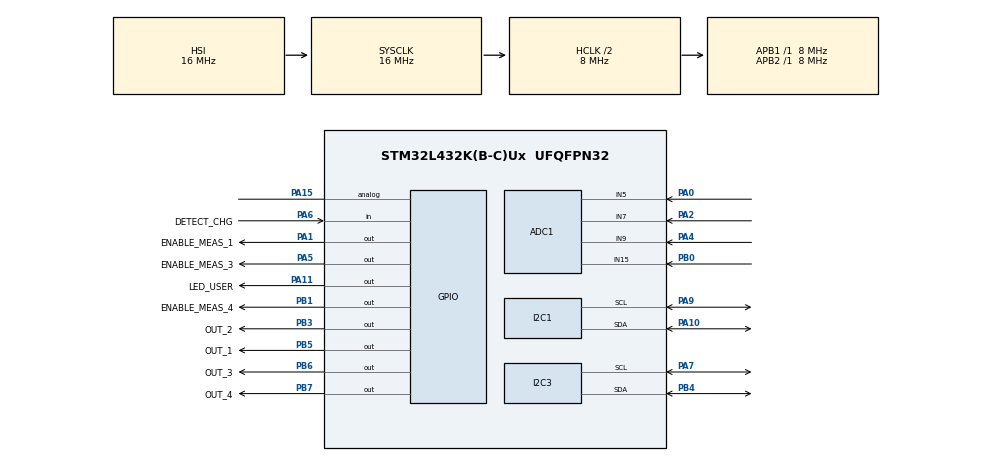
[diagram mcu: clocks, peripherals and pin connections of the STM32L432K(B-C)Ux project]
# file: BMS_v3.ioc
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ADC1.Channel-0\#ChannelRegularConversion=ADC_CHANNEL_5
ADC1.NbrOfConversion=1
ADC1.NbrOfConversionFlag=1
ADC1.master=1
I2C1.OwnAddress=4
I2C1.Timing=0x2000090E
I2C3.Timing=0x2000090E
Mcu.Family=STM32L4
Mcu.Name=STM32L432K(B-C)Ux
Mcu.Package=UFQFPN32
NVIC.I2C1_ER_IRQn=true\:0\:0\:false\:false\:true\:true\:true\:true
NVIC.I2C1_EV_IRQn=true\:0\:0\:false\:false\:true\:true\:true\:true
NVIC.PriorityGroup=NVIC_PRIORITYGROUP_4
PA0.Signal=ADCx_IN5
PA1.GPIO_Label=ENABLE_MEAS_1
PA1.Signal=GPIO_Output
PA10.Mode=I2C
PA10.Signal=I2C1_SDA
PA11.GPIO_Label=LED_USER
PA11.Signal=GPIO_Output
PA13\ (JTMS-SWDIO).Mode=Serial_Wire
PA13\ (JTMS-SWDIO).Signal=SYS_JTMS-SWDIO
PA14\ (JTCK-SWCLK).Mode=Serial_Wire
PA14\ (JTCK-SWCLK).Signal=SYS_JTCK-SWCLK
PA15\ (JTDI).Signal=GPIO_Analog
PA2.Signal=ADCx_IN7
PA4.Signal=ADCx_IN9
PA5.GPIO_Label=ENABLE_MEAS_3
PA5.Signal=GPIO_Output
PA6.GPIO_Label=DETECT_CHG
PA6.GPIO_PuPd=GPIO_PULLUP
PA6.Signal=GPIO_Input
PA7.Mode=I2C
PA7.Signal=I2C3_SCL
PA9.Mode=I2C
PA9.Signal=I2C1_SCL
PB0.Signal=ADCx_IN15
PB1.GPIO_Label=ENABLE_MEAS_4
PB1.Signal=GPIO_Output
PB3\ (JTDO-TRACESWO).GPIO_Label=OUT_2
PB3\ (JTDO-TRACESWO).Signal=GPIO_Output
PB4\ (NJTRST).Mode=I2C
PB4\ (NJTRST).Signal=I2C3_SDA
PB5.GPIO_Label=OUT_1
PB5.Signal=GPIO_Output
PB6.GPIO_Label=OUT_3
PB6.Signal=GPIO_Output
PB7.GPIO_Label=OUT_4
PB7.Signal=GPIO_Output
ProjectManager.HeapSize=0x200
ProjectManager.StackSize=0x400
ProjectManager.TargetToolchain=STM32CubeIDE
RCC.ADCFreq_Value=32000000
RCC.AHBCLKDivider=RCC_SYSCLK_DIV2
RCC.AHBFreq_Value=8000000
RCC.APB1Freq_Value=8000000
RCC.APB1TimFreq_Value=8000000
RCC.APB2Freq_Value=8000000
RCC.APB2TimFreq_Value=8000000
RCC.CortexFreq_Value=8000000
RCC.HCLKFreq_Value=8000000
RCC.HSE_VALUE=8000000
RCC.HSI48_VALUE=48000000
RCC.HSI_VALUE=16000000
RCC.LSE_VALUE=32768
RCC.MSI_VALUE=4000000
RCC.PLLSAI1N=16
RCC.SYSCLKFreq_VALUE=16000000
RCC.SYSCLKSource=RCC_SYSCLKSOURCE_HSI
RCC.USBFreq_Value=32000000
RCC.VCOOutputFreq_Value=32000000
SH.ADCx_IN15.0=ADC1_IN15,IN15-Single-Ended
SH.ADCx_IN5.0=ADC1_IN5,IN5-Single-Ended
SH.ADCx_IN7.0=ADC1_IN7,IN7-Single-Ended
SH.ADCx_IN9.0=ADC1_IN9,IN9-Single-Ended
board=custom

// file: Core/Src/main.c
/* USER CODE BEGIN Header */
/**
  ******************************************************************************
  * @file           : main.c
  * @brief          : Main program body
  ******************************************************************************
  * @attention
  *
  * Copyright (c) 2022 STMicroelectronics.
  * All rights reserved.
  *
  * This software is licensed under terms that can be found in the LICENSE file
  * in the root directory of this software component.
  * If no LICENSE file comes with this software, it is provided AS-IS.
  *
  ******************************************************************************
  */
/* USER CODE END Header */
#include "main.h"

ADC_HandleTypeDef hadc1;

I2C_HandleTypeDef hi2c1;
I2C_HandleTypeDef hi2c3;

void SystemClock_Config(void);
static void MX_GPIO_Init(void);
static void MX_I2C1_Init(void);
static void MX_ADC1_Init(void);
static void MX_I2C3_Init(void);

int main(void)
{

  /* MCU Configuration--------------------------------------------------------*/

  /* Reset of all peripherals, Initializes the Flash interface and the Systick. */
  HAL_Init();

  /* Configure the system clock */
  SystemClock_Config();

  /* Initialize all configured peripherals */
  MX_GPIO_Init();
  MX_I2C1_Init();
  MX_ADC1_Init();
  MX_I2C3_Init();
  /* USER CODE BEGIN 2 */

  firmware();

  HAL_Delay(250);
  // Set all Outputs to ON

//  HAL_GPIO_TogglePin(LED_LOW_GPIO_Port, LED_LOW_Pin);
  /* USER CODE END 2 */

  /* Infinite loop */
  while (1)
  {

    /* USER CODE BEGIN 3 */
	  HAL_GPIO_WritePin(OUT_4_GPIO_Port, OUT_4_Pin, 1);

	  if (HAL_GPIO_ReadPin(DETECT_CHG_GPIO_Port, DETECT_CHG_Pin)) {
		  HAL_GPIO_WritePin(OUT_1_GPIO_Port, OUT_1_Pin, 1);
		  HAL_GPIO_WritePin(OUT_2_GPIO_Port, OUT_2_Pin, 1);
		  HAL_GPIO_WritePin(OUT_3_GPIO_Port, OUT_3_Pin, 1);
	  } else {
		  HAL_GPIO_WritePin(OUT_1_GPIO_Port, OUT_1_Pin, 0);
		  HAL_GPIO_WritePin(OUT_2_GPIO_Port, OUT_2_Pin, 0);
		  HAL_GPIO_WritePin(OUT_3_GPIO_Port, OUT_3_Pin, 0);
	  }

	  HAL_GPIO_TogglePin(LED_USER_GPIO_Port, LED_USER_Pin);
	  HAL_Delay(250);
  }
  /* USER CODE END 3 */
}

void SystemClock_Config(void)
{
  RCC_OscInitTypeDef RCC_OscInitStruct = {0};
  RCC_ClkInitTypeDef RCC_ClkInitStruct = {0};

  /** Configure the main internal regulator output voltage
  */
  if (HAL_PWREx_ControlVoltageScaling(PWR_REGULATOR_VOLTAGE_SCALE1) != HAL_OK)
  {
    Error_Handler();
  }

  /** Initializes the RCC Oscillators according to the specified parameters
  * in the RCC_OscInitTypeDef structure.
  */
  RCC_OscInitStruct.OscillatorType = RCC_OSCILLATORTYPE_HSI|RCC_OSCILLATORTYPE_MSI;
  RCC_OscInitStruct.HSIState = RCC_HSI_ON;
  RCC_OscInitStruct.HSICalibrationValue = RCC_HSICALIBRATION_DEFAULT;
  RCC_OscInitStruct.MSIState = RCC_MSI_ON;
  RCC_OscInitStruct.MSICalibrationValue = 0;
  RCC_OscInitStruct.MSIClockRange = RCC_MSIRANGE_6;
  RCC_OscInitStruct.PLL.PLLState = RCC_PLL_NONE;
  if (HAL_RCC_OscConfig(&RCC_OscInitStruct) != HAL_OK)
  {
    Error_Handler();
  }

  /** Initializes the CPU, AHB and APB buses clocks
  */
  RCC_ClkInitStruct.ClockType = RCC_CLOCKTYPE_HCLK|RCC_CLOCKTYPE_SYSCLK
                              |RCC_CLOCKTYPE_PCLK1|RCC_CLOCKTYPE_PCLK2;
  RCC_ClkInitStruct.SYSCLKSource = RCC_SYSCLKSOURCE_HSI;
  RCC_ClkInitStruct.AHBCLKDivider = RCC_SYSCLK_DIV2;
  RCC_ClkInitStruct.APB1CLKDivider = RCC_HCLK_DIV1;
  RCC_ClkInitStruct.APB2CLKDivider = RCC_HCLK_DIV1;

  if (HAL_RCC_ClockConfig(&RCC_ClkInitStruct, FLASH_LATENCY_0) != HAL_OK)
  {
    Error_Handler();
  }
}

static void MX_ADC1_Init(void)
{

  ADC_ChannelConfTypeDef sConfig = {0};

  /** Common config
  */
  hadc1.Instance = ADC1;
  hadc1.Init.ClockPrescaler = ADC_CLOCK_ASYNC_DIV1;
  hadc1.Init.Resolution = ADC_RESOLUTION_12B;
  hadc1.Init.DataAlign = ADC_DATAALIGN_RIGHT;
  hadc1.Init.ScanConvMode = ADC_SCAN_DISABLE;
  hadc1.Init.EOCSelection = ADC_EOC_SINGLE_CONV;
  hadc1.Init.LowPowerAutoWait = DISABLE;
  hadc1.Init.ContinuousConvMode = DISABLE;
  hadc1.Init.NbrOfConversion = 1;
  hadc1.Init.DiscontinuousConvMode = DISABLE;
  hadc1.Init.ExternalTrigConv = ADC_SOFTWARE_START;
  hadc1.Init.ExternalTrigConvEdge = ADC_EXTERNALTRIGCONVEDGE_NONE;
  hadc1.Init.DMAContinuousRequests = DISABLE;
  hadc1.Init.Overrun = ADC_OVR_DATA_PRESERVED;
  hadc1.Init.OversamplingMode = DISABLE;
  if (HAL_ADC_Init(&hadc1) != HAL_OK)
  {
    Error_Handler();
  }

  /** Configure Regular Channel
  */
  sConfig.Channel = ADC_CHANNEL_5;
  sConfig.Rank = ADC_REGULAR_RANK_1;
  sConfig.SamplingTime = ADC_SAMPLETIME_2CYCLES_5;
  sConfig.SingleDiff = ADC_SINGLE_ENDED;
  sConfig.OffsetNumber = ADC_OFFSET_NONE;
  sConfig.Offset = 0;
  if (HAL_ADC_ConfigChannel(&hadc1, &sConfig) != HAL_OK)
  {
    Error_Handler();
  }

}

static void MX_I2C1_Init(void)
{

  hi2c1.Instance = I2C1;
  hi2c1.Init.Timing = 0x2000090E;
  hi2c1.Init.OwnAddress1 = 8;
  hi2c1.Init.AddressingMode = I2C_ADDRESSINGMODE_7BIT;
  hi2c1.Init.DualAddressMode = I2C_DUALADDRESS_DISABLE;
  hi2c1.Init.OwnAddress2 = 0;
  hi2c1.Init.OwnAddress2Masks = I2C_OA2_NOMASK;
  hi2c1.Init.GeneralCallMode = I2C_GENERALCALL_DISABLE;
  hi2c1.Init.NoStretchMode = I2C_NOSTRETCH_DISABLE;
  if (HAL_I2C_Init(&hi2c1) != HAL_OK)
  {
    Error_Handler();
  }

  /** Configure Analogue filter
  */
  if (HAL_I2CEx_ConfigAnalogFilter(&hi2c1, I2C_ANALOGFILTER_ENABLE) != HAL_OK)
  {
    Error_Handler();
  }

  /** Configure Digital filter
  */
  if (HAL_I2CEx_ConfigDigitalFilter(&hi2c1, 0) != HAL_OK)
  {
    Error_Handler();
  }

}

static void MX_I2C3_Init(void)
{

  hi2c3.Instance = I2C3;
  hi2c3.Init.Timing = 0x2000090E;
  hi2c3.Init.OwnAddress1 = 0;
  hi2c3.Init.AddressingMode = I2C_ADDRESSINGMODE_7BIT;
  hi2c3.Init.DualAddressMode = I2C_DUALADDRESS_DISABLE;
  hi2c3.Init.OwnAddress2 = 0;
  hi2c3.Init.OwnAddress2Masks = I2C_OA2_NOMASK;
  hi2c3.Init.GeneralCallMode = I2C_GENERALCALL_DISABLE;
  hi2c3.Init.NoStretchMode = I2C_NOSTRETCH_DISABLE;
  if (HAL_I2C_Init(&hi2c3) != HAL_OK)
  {
    Error_Handler();
  }

  /** Configure Analogue filter
  */
  if (HAL_I2CEx_ConfigAnalogFilter(&hi2c3, I2C_ANALOGFILTER_ENABLE) != HAL_OK)
  {
    Error_Handler();
  }

  /** Configure Digital filter
  */
  if (HAL_I2CEx_ConfigDigitalFilter(&hi2c3, 0) != HAL_OK)
  {
    Error_Handler();
  }

}

static void MX_GPIO_Init(void)
{
  GPIO_InitTypeDef GPIO_InitStruct = {0};

  /* GPIO Ports Clock Enable */
  __HAL_RCC_GPIOA_CLK_ENABLE();
  __HAL_RCC_GPIOB_CLK_ENABLE();

  /*Configure GPIO pin Output Level */
  HAL_GPIO_WritePin(GPIOA, ENABLE_MEAS_1_Pin|ENABLE_MEAS_3_Pin|LED_USER_Pin, GPIO_PIN_RESET);

  /*Configure GPIO pin Output Level */
  HAL_GPIO_WritePin(GPIOB, ENABLE_MEAS_4_Pin|OUT_2_Pin|OUT_1_Pin|OUT_3_Pin
                          |OUT_4_Pin, GPIO_PIN_RESET);

  /*Configure GPIO pins : ENABLE_MEAS_1_Pin ENABLE_MEAS_3_Pin LED_USER_Pin */
  GPIO_InitStruct.Pin = ENABLE_MEAS_1_Pin|ENABLE_MEAS_3_Pin|LED_USER_Pin;
  GPIO_InitStruct.Mode = GPIO_MODE_OUTPUT_PP;
  GPIO_InitStruct.Pull = GPIO_NOPULL;
  GPIO_InitStruct.Speed = GPIO_SPEED_FREQ_LOW;
  HAL_GPIO_Init(GPIOA, &GPIO_InitStruct);

  /*Configure GPIO pin : DETECT_CHG_Pin */
  GPIO_InitStruct.Pin = DETECT_CHG_Pin;
  GPIO_InitStruct.Mode = GPIO_MODE_INPUT;
  GPIO_InitStruct.Pull = GPIO_PULLUP;
  HAL_GPIO_Init(DETECT_CHG_GPIO_Port, &GPIO_InitStruct);

  /*Configure GPIO pins : ENABLE_MEAS_4_Pin OUT_2_Pin OUT_1_Pin OUT_3_Pin
                           OUT_4_Pin */
  GPIO_InitStruct.Pin = ENABLE_MEAS_4_Pin|OUT_2_Pin|OUT_1_Pin|OUT_3_Pin
                          |OUT_4_Pin;
  GPIO_InitStruct.Mode = GPIO_MODE_OUTPUT_PP;
  GPIO_InitStruct.Pull = GPIO_NOPULL;
  GPIO_InitStruct.Speed = GPIO_SPEED_FREQ_LOW;
  HAL_GPIO_Init(GPIOB, &GPIO_InitStruct);

  /*Configure GPIO pin : PA15 */
  GPIO_InitStruct.Pin = GPIO_PIN_15;
  GPIO_InitStruct.Mode = GPIO_MODE_ANALOG;
  GPIO_InitStruct.Pull = GPIO_NOPULL;
  HAL_GPIO_Init(GPIOA, &GPIO_InitStruct);

}

void Error_Handler(void)
{
  __disable_irq();
  while (1)
  {
  }
}
